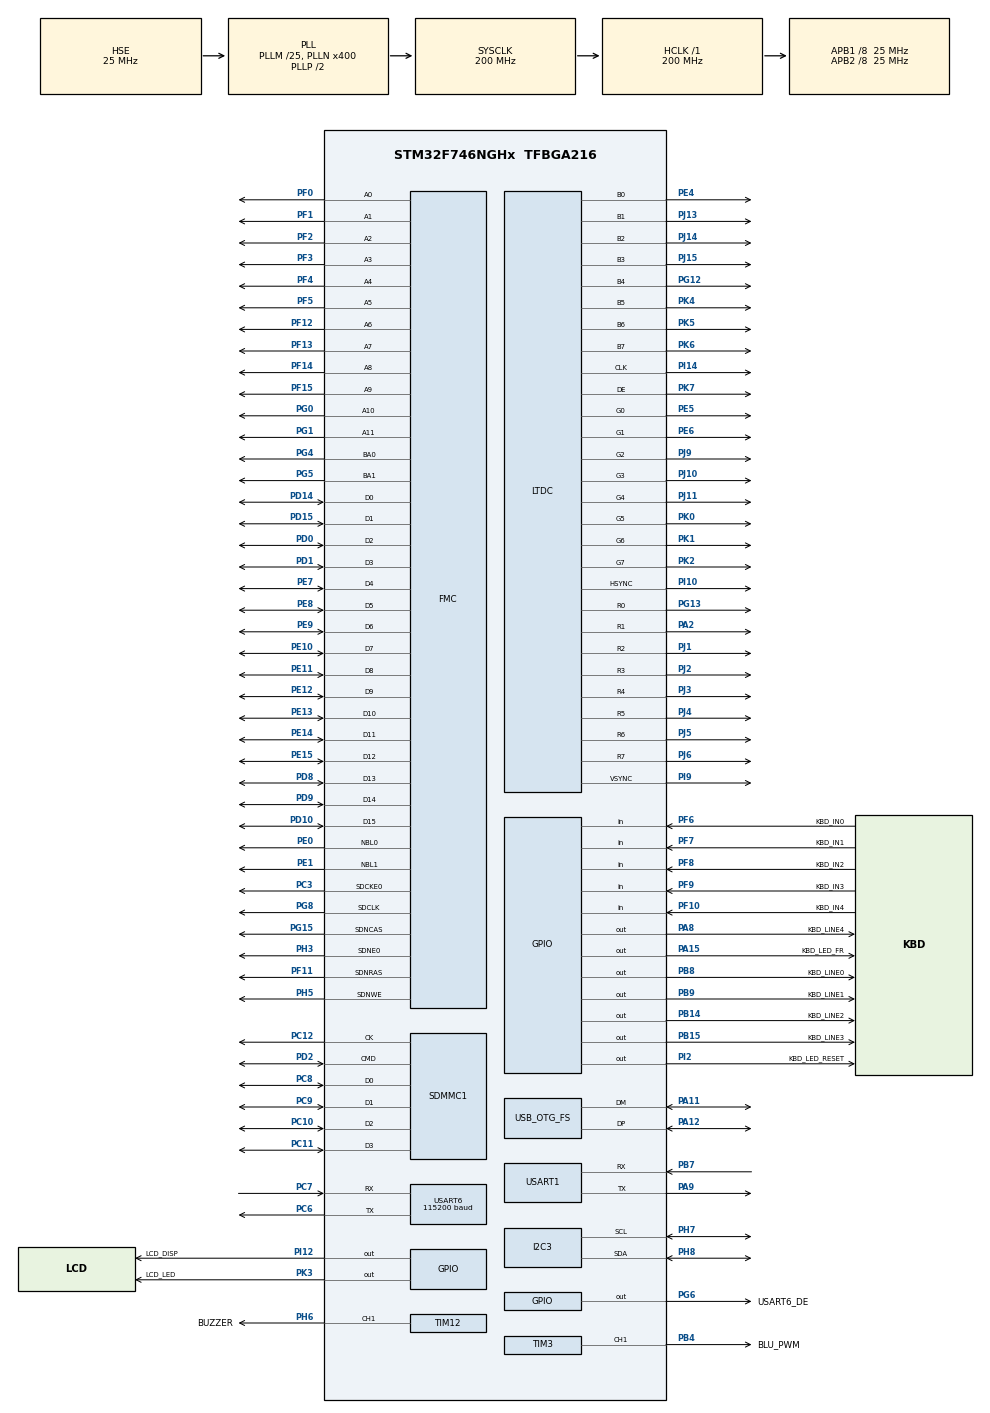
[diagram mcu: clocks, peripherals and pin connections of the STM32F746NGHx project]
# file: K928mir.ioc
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CORTEX_M7.AccessPermission-Cortex_Memory_Protection_Unit_Region0_Settings=MPU_REGION_FULL_ACCESS
CORTEX_M7.BaseAddress-Cortex_Memory_Protection_Unit_Region0_Settings=0xC0000000
CORTEX_M7.CPU_DCache=Enabled
CORTEX_M7.CPU_ICache=Enabled
CORTEX_M7.Enable-Cortex_Memory_Protection_Unit_Region0_Settings=MPU_REGION_ENABLE
CORTEX_M7.IsCacheable-Cortex_Memory_Protection_Unit_Region0_Settings=MPU_ACCESS_CACHEABLE
CORTEX_M7.MPU_Control=MPU_PRIVILEGED_DEFAULT
CORTEX_M7.Size-Cortex_Memory_Protection_Unit_Region0_Settings=MPU_REGION_SIZE_4MB
DMA2D.ColorMode=DMA2D_OUTPUT_RGB565
FATFS.USE_DMA_CODE_SD=0
FATFS._MAX_SS=4096
FMC.CASLatency1=FMC_SDRAM_CAS_LATENCY_2
FMC.ExitSelfRefreshDelay1=6
FMC.LoadToActiveDelay1=2
FMC.RCDDelay1=2
FMC.RPDelay1=2
FMC.ReadBurst1=FMC_SDRAM_RBURST_ENABLE
FMC.ReadPipeDelay1=FMC_SDRAM_RPIPE_DELAY_0
FMC.RowCycleDelay1=6
FMC.RowCycleDelay2=6
FMC.SDClockPeriod1=FMC_SDRAM_CLOCK_PERIOD_2
FMC.SDClockPeriod2=FMC_SDRAM_CLOCK_PERIOD_2
FMC.SelfRefreshTime1=4
FMC.WriteRecoveryTime1=2
I2C3.OwnAddress=112
I2C3.Timing=0x00606092
LTDC.ActiveH=272
LTDC.ActiveW=480
LTDC.Alpha_L0=0
LTDC.FBStartAdress_L1=0
LTDC.HBP=13
LTDC.HFP=32
LTDC.HSync=30
LTDC.ImageHeight_L0=272
LTDC.ImageHeight_L1=272
LTDC.ImageWidth_L0=480
LTDC.ImageWidth_L1=480
LTDC.Layers=1
LTDC.PixelFormat_L0=LTDC_PIXEL_FORMAT_RGB565
LTDC.PixelFormat_L1=LTDC_PIXEL_FORMAT_RGB565
LTDC.VBP=2
LTDC.VFP=2
LTDC.VSync=10
LTDC.WindowX1_L0=480
LTDC.WindowX1_L1=480
LTDC.WindowY1_L0=272
LTDC.WindowY1_L1=272
Mcu.Family=STM32F7
Mcu.Name=STM32F746NGHx
Mcu.Package=TFBGA216
Mcu.UserConstants=UC_LEDLIGHT_PERIOD,50000;UC_MAINTIC_PERIOD,50000
NVIC.LTDC_IRQn=true\:0\:0\:false\:false\:true\:true
NVIC.OTG_FS_IRQn=true\:0\:0\:false\:false\:true\:false
NVIC.PriorityGroup=NVIC_PRIORITYGROUP_4
NVIC.USART1_IRQn=true\:0\:0\:false\:false\:true\:true
NVIC.USART6_IRQn=true\:0\:0\:false\:false\:true\:true
PA11.Mode=Device_Only
PA11.Signal=USB_OTG_FS_DM
PA12.Mode=Device_Only
PA12.Signal=USB_OTG_FS_DP
PA13.Mode=Serial_Wire
PA13.Signal=SYS_JTMS-SWDIO
PA14.Mode=Serial_Wire
PA14.Signal=SYS_JTCK-SWCLK
PA15.GPIO_Label=KBD_LED_FR
PA15.PinState=GPIO_PIN_RESET
PA15.Signal=GPIO_Output
PA2.Mode=RGB888
PA2.Signal=LTDC_R1
PA8.GPIO_Label=KBD_LINE4
PA8.GPIO_ModeDefaultOutputPP=GPIO_MODE_OUTPUT_OD
PA8.PinState=GPIO_PIN_SET
PA8.Signal=GPIO_Output
PA9.Mode=Asynchronous
PA9.Signal=USART1_TX
PB14.GPIO_Label=KBD_LINE2
PB14.GPIO_ModeDefaultOutputPP=GPIO_MODE_OUTPUT_OD
PB14.GPIO_Speed=GPIO_SPEED_FREQ_LOW
PB14.PinState=GPIO_PIN_SET
PB14.Signal=GPIO_Output
PB15.GPIO_Label=KBD_LINE3
PB15.GPIO_ModeDefaultOutputPP=GPIO_MODE_OUTPUT_OD
PB15.PinState=GPIO_PIN_SET
PB15.Signal=GPIO_Output
PB4.GPIO_Label=BLU_PWM
PB4.Signal=S_TIM3_CH1
PB7.Mode=Asynchronous
PB7.Signal=USART1_RX
PB8.GPIO_Label=KBD_LINE0
PB8.GPIO_ModeDefaultOutputPP=GPIO_MODE_OUTPUT_OD
PB8.GPIO_Speed=GPIO_SPEED_FREQ_LOW
PB8.PinState=GPIO_PIN_SET
PB8.Signal=GPIO_Output
PB9.GPIO_Label=KBD_LINE1
PB9.GPIO_ModeDefaultOutputPP=GPIO_MODE_OUTPUT_OD
PB9.GPIO_Speed=GPIO_SPEED_FREQ_LOW
PB9.PinState=GPIO_PIN_SET
PB9.Signal=GPIO_Output
PC10.GPIO_PuPd=GPIO_PULLUP
PC10.Mode=SD_4_bits_Wide_bus
PC10.Signal=SDMMC1_D2
PC11.GPIO_PuPd=GPIO_PULLUP
PC11.Mode=SD_4_bits_Wide_bus
PC11.Signal=SDMMC1_D3
PC12.Mode=SD_4_bits_Wide_bus
PC12.Signal=SDMMC1_CK
PC3.Mode=SdramChipSelect1_1
PC3.Signal=FMC_SDCKE0
PC6.Mode=Asynchronous
PC6.Signal=USART6_TX
PC7.Mode=Asynchronous
PC7.Signal=USART6_RX
PC8.GPIO_PuPd=GPIO_PULLUP
PC8.Mode=SD_4_bits_Wide_bus
PC8.Signal=SDMMC1_D0
PC9.GPIO_PuPd=GPIO_PULLUP
PC9.Mode=SD_4_bits_Wide_bus
PC9.Signal=SDMMC1_D1
PD0.Signal=FMC_D2_DA2
PD1.Signal=FMC_D3_DA3
PD10.Signal=FMC_D15_DA15
PD14.Signal=FMC_D0_DA0
PD15.Signal=FMC_D1_DA1
PD2.GPIO_PuPd=GPIO_PULLUP
PD2.Mode=SD_4_bits_Wide_bus
PD2.Signal=SDMMC1_CMD
PD8.Signal=FMC_D13_DA13
PD9.Signal=FMC_D14_DA14
PE0.Signal=FMC_NBL0
PE1.Signal=FMC_NBL1
PE10.Signal=FMC_D7_DA7
PE11.Signal=FMC_D8_DA8
PE12.Signal=FMC_D9_DA9
PE13.Signal=FMC_D10_DA10
PE14.Signal=FMC_D11_DA11
PE15.Signal=FMC_D12_DA12
PE4.Mode=RGB888
PE4.Signal=LTDC_B0
PE5.Mode=RGB888
PE5.Signal=LTDC_G0
PE6.Mode=RGB888
PE6.Signal=LTDC_G1
PE7.Signal=FMC_D4_DA4
PE8.Signal=FMC_D5_DA5
PE9.Signal=FMC_D6_DA6
PF0.Signal=FMC_A0
PF1.Signal=FMC_A1
PF10.GPIO_Label=KBD_IN4
PF10.Signal=GPIO_Input
PF11.Signal=FMC_SDNRAS
PF12.Signal=FMC_A6
PF13.Signal=FMC_A7
PF14.Signal=FMC_A8
PF15.Signal=FMC_A9
PF2.Signal=FMC_A2
PF3.Signal=FMC_A3
PF4.Signal=FMC_A4
PF5.Signal=FMC_A5
PF6.GPIO_Label=KBD_IN0
PF6.Signal=GPIO_Input
PF7.GPIO_Label=KBD_IN1
PF7.Signal=GPIO_Input
PF8.GPIO_Label=KBD_IN2
PF8.Signal=GPIO_Input
PF9.GPIO_Label=KBD_IN3
PF9.Signal=GPIO_Input
PG0.Signal=FMC_A10
PG1.Signal=FMC_A11
PG12.GPIO_Speed=GPIO_SPEED_FREQ_HIGH
PG12.Mode=RGB888
PG12.Signal=LTDC_B4
PG13.Mode=RGB888
PG13.Signal=LTDC_R0
PG15.Signal=FMC_SDNCAS
PG4.Signal=FMC_A14_BA0
PG5.Signal=FMC_A15_BA1
PG6.GPIO_Label=USART6_DE
PG6.PinState=GPIO_PIN_SET
PG6.Signal=GPIO_Output
PG8.Signal=FMC_SDCLK
PH0/OSC_IN.Mode=HSE-External-Oscillator
PH0/OSC_IN.Signal=RCC_OSC_IN
PH1/OSC_OUT.Mode=HSE-External-Oscillator
PH1/OSC_OUT.Signal=RCC_OSC_OUT
PH3.Mode=SdramChipSelect1_1
PH3.Signal=FMC_SDNE0
PH5.Signal=FMC_SDNWE
PH6.GPIO_Label=BUZZER
PH6.GPIO_PuPd=GPIO_PULLUP
PH6.Signal=S_TIM12_CH1
PH7.Mode=I2C
PH7.Signal=I2C3_SCL
PH8.Mode=I2C
PH8.Signal=I2C3_SDA
PI10.GPIO_Speed=GPIO_SPEED_FREQ_HIGH
PI10.Mode=RGB888
PI10.Signal=LTDC_HSYNC
PI12.GPIO_Label=LCD_DISP
PI12.PinState=GPIO_PIN_RESET
PI12.Signal=GPIO_Output
PI14.GPIO_Speed=GPIO_SPEED_FREQ_HIGH
PI14.Mode=RGB888
PI14.Signal=LTDC_CLK
PI2.GPIO_Label=KBD_LED_RESET
PI2.PinState=GPIO_PIN_RESET
PI2.Signal=GPIO_Output
PI9.GPIO_Speed=GPIO_SPEED_FREQ_HIGH
PI9.Mode=RGB888
PI9.Signal=LTDC_VSYNC
PJ1.GPIO_Speed=GPIO_SPEED_FREQ_HIGH
PJ1.Mode=RGB888
PJ1.Signal=LTDC_R2
PJ10.GPIO_Speed=GPIO_SPEED_FREQ_HIGH
PJ10.Mode=RGB888
PJ10.Signal=LTDC_G3
PJ11.GPIO_Speed=GPIO_SPEED_FREQ_HIGH
PJ11.Mode=RGB888
PJ11.Signal=LTDC_G4
PJ13.Mode=RGB888
PJ13.Signal=LTDC_B1
PJ14.GPIO_Speed=GPIO_SPEED_FREQ_HIGH
PJ14.Mode=RGB888
PJ14.Signal=LTDC_B2
PJ15.GPIO_Speed=GPIO_SPEED_FREQ_HIGH
PJ15.Mode=RGB888
PJ15.Signal=LTDC_B3
PJ2.GPIO_Speed=GPIO_SPEED_FREQ_HIGH
PJ2.Mode=RGB888
PJ2.Signal=LTDC_R3
PJ3.GPIO_Speed=GPIO_SPEED_FREQ_HIGH
PJ3.Mode=RGB888
PJ3.Signal=LTDC_R4
PJ4.GPIO_Speed=GPIO_SPEED_FREQ_HIGH
PJ4.Mode=RGB888
PJ4.Signal=LTDC_R5
PJ5.GPIO_Speed=GPIO_SPEED_FREQ_HIGH
PJ5.Mode=RGB888
PJ5.Signal=LTDC_R6
PJ6.GPIO_Speed=GPIO_SPEED_FREQ_HIGH
PJ6.Mode=RGB888
PJ6.Signal=LTDC_R7
PJ9.GPIO_Speed=GPIO_SPEED_FREQ_HIGH
PJ9.Mode=RGB888
PJ9.Signal=LTDC_G2
PK0.GPIO_Speed=GPIO_SPEED_FREQ_HIGH
PK0.Mode=RGB888
PK0.Signal=LTDC_G5
PK1.GPIO_Speed=GPIO_SPEED_FREQ_HIGH
PK1.Mode=RGB888
PK1.Signal=LTDC_G6
PK2.GPIO_Speed=GPIO_SPEED_FREQ_HIGH
PK2.Mode=RGB888
PK2.Signal=LTDC_G7
PK3.GPIO_Label=LCD_LED
PK3.PinState=GPIO_PIN_RESET
PK3.Signal=GPIO_Output
PK4.GPIO_Speed=GPIO_SPEED_FREQ_HIGH
PK4.Mode=RGB888
PK4.Signal=LTDC_B5
PK5.GPIO_Speed=GPIO_SPEED_FREQ_HIGH
PK5.Mode=RGB888
PK5.Signal=LTDC_B6
PK6.GPIO_Speed=GPIO_SPEED_FREQ_HIGH
PK6.Mode=RGB888
PK6.Signal=LTDC_B7
PK7.GPIO_Speed=GPIO_SPEED_FREQ_HIGH
PK7.Mode=RGB888
PK7.Signal=LTDC_DE
ProjectManager.HeapSize=0x4000
ProjectManager.StackSize=0x8000
ProjectManager.TargetToolchain=EWARM
RCC.AHBFreq_Value=200000000
RCC.APB1CLKDivider=RCC_HCLK_DIV8
RCC.APB1Freq_Value=25000000
RCC.APB1TimFreq_Value=50000000
RCC.APB2CLKDivider=RCC_HCLK_DIV8
RCC.APB2Freq_Value=25000000
RCC.APB2TimFreq_Value=50000000
RCC.CortexFreq_Value=200000000
RCC.HCLKFreq_Value=200000000
RCC.HSE_VALUE=25000000
RCC.HSI_VALUE=16000000
RCC.LSE_VALUE=32768
RCC.PLL48CLockSelection=RCC_CLK48SOURCE_PLLSAIP
RCC.PLLM=25
RCC.PLLN=400
RCC.PLLQ=8
RCC.PLLSAIP=RCC_PLLSAIP_DIV4
RCC.PLLSAIR=5
RCC.PLLSAIRDiv=RCC_PLLSAIDIVR_4
RCC.SDMMCClockSelection=RCC_SDMMC1CLKSOURCE_CLK48
RCC.SYSCLKFreq_VALUE=200000000
RCC.SYSCLKSource=RCC_SYSCLKSOURCE_PLLCLK
RCC.USBFreq_Value=48000000
RCC.VCOOutputFreq_Value=400000000
SH.FMC_A0.0=FMC_A0,12b-sda1
SH.FMC_A1.0=FMC_A1,12b-sda1
SH.FMC_A10.0=FMC_A10,12b-sda1
SH.FMC_A11.0=FMC_A11,12b-sda1
SH.FMC_A14_BA0.0=FMC_BA0,FourSdramBanks1
SH.FMC_A15_BA1.0=FMC_BA1,FourSdramBanks1
SH.FMC_A2.0=FMC_A2,12b-sda1
SH.FMC_A3.0=FMC_A3,12b-sda1
SH.FMC_A4.0=FMC_A4,12b-sda1
SH.FMC_A5.0=FMC_A5,12b-sda1
SH.FMC_A6.0=FMC_A6,12b-sda1
SH.FMC_A7.0=FMC_A7,12b-sda1
SH.FMC_A8.0=FMC_A8,12b-sda1
SH.FMC_A9.0=FMC_A9,12b-sda1
SH.FMC_D0_DA0.0=FMC_D0,sd-16b-d1
SH.FMC_D10_DA10.0=FMC_D10,sd-16b-d1
SH.FMC_D11_DA11.0=FMC_D11,sd-16b-d1
SH.FMC_D12_DA12.0=FMC_D12,sd-16b-d1
SH.FMC_D13_DA13.0=FMC_D13,sd-16b-d1
SH.FMC_D14_DA14.0=FMC_D14,sd-16b-d1
SH.FMC_D15_DA15.0=FMC_D15,sd-16b-d1
SH.FMC_D1_DA1.0=FMC_D1,sd-16b-d1
SH.FMC_D2_DA2.0=FMC_D2,sd-16b-d1
SH.FMC_D3_DA3.0=FMC_D3,sd-16b-d1
SH.FMC_D4_DA4.0=FMC_D4,sd-16b-d1
SH.FMC_D5_DA5.0=FMC_D5,sd-16b-d1
SH.FMC_D6_DA6.0=FMC_D6,sd-16b-d1
SH.FMC_D7_DA7.0=FMC_D7,sd-16b-d1
SH.FMC_D8_DA8.0=FMC_D8,sd-16b-d1
SH.FMC_D9_DA9.0=FMC_D9,sd-16b-d1
SH.FMC_NBL0.0=FMC_NBL0,Sd2ByteEnable1
SH.FMC_NBL1.0=FMC_NBL1,Sd2ByteEnable1
SH.FMC_SDCLK.0=FMC_SDCLK,12b-sda1
SH.FMC_SDNCAS.0=FMC_SDNCAS,12b-sda1
SH.FMC_SDNRAS.0=FMC_SDNRAS,12b-sda1
SH.FMC_SDNWE.0=FMC_SDNWE,12b-sda1
SH.S_TIM12_CH1.0=TIM12_CH1,PWM Generation1 CH1
SH.S_TIM3_CH1.0=TIM3_CH1,PWM Generation1 CH1
TIM10.ClockDivision=TIM_CLOCKDIVISION_DIV1
TIM10.Period=UC_MAINTIC_PERIOD
TIM10.Prescaler=1
TIM12.Channel-PWM\ Generation1\ CH1=TIM_CHANNEL_1
TIM12.OCFastMode_PWM-PWM\ Generation1\ CH1=TIM_OCFAST_DISABLE
TIM12.OCPolarity_1=TIM_OCPOLARITY_HIGH
TIM12.Period=4999
TIM12.Prescaler=4
TIM12.Pulse-PWM\ Generation1\ CH1=2500
TIM3.AutoReloadPreload=TIM_AUTORELOAD_PRELOAD_ENABLE
TIM3.Channel-PWM\ Generation1\ CH1=TIM_CHANNEL_1
TIM3.ClockDivision=TIM_CLOCKDIVISION_DIV1
TIM3.OCFastMode_PWM-PWM\ Generation1\ CH1=TIM_OCFAST_ENABLE
TIM3.OCMode_PWM-PWM\ Generation1\ CH1=TIM_OCMODE_PWM2
TIM3.Period=UC_LEDLIGHT_PERIOD
TIM3.Prescaler=6
TIM3.Pulse-PWM\ Generation1\ CH1=(UC_LEDLIGHT_PERIOD / 10)*9
USART1.Parity=PARITY_EVEN
USART1.VirtualMode-Asynchronous=VM_ASYNC
USART1.WordLength=WORDLENGTH_9B
USART6.BaudRate=115200
USART6.Parity=PARITY_EVEN
USART6.VirtualMode-Asynchronous=VM_ASYNC
USART6.WordLength=WORDLENGTH_9B
USB_DEVICE.CLASS_NAME_FS=CDC
USB_DEVICE.VirtualMode-CDC_FS=Cdc
USB_DEVICE.VirtualModeFS=Cdc_FS
USB_OTG_FS.VirtualMode=Device_Only
VP_DMA2D_VS_DMA2D.Mode=DMA2D_Activate
VP_FATFS_VS_SDIO.Mode=SDIO
VP_RNG_VS_RNG.Mode=RNG_Activate
VP_TIM10_VS_ClockSourceINT.Mode=Enable_Timer
VP_TIM3_VS_ClockSourceINT.Mode=Internal
VP_USB_DEVICE_VS_USB_DEVICE_CDC_FS.Mode=CDC_FS
board=K928mir

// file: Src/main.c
/**
  ******************************************************************************
  * @file           : main.c
  * @brief          : Main program body
  ******************************************************************************
  * This notice applies to any and all portions of this file
  * that are not between comment pairs USER CODE BEGIN and
  * USER CODE END. Other portions of this file, whether
  * inserted by the user or by software development tools
  * are owned by their respective copyright owners.
  *
  * Copyright (c) 2019 STMicroelectronics International N.V.
  * All rights reserved.
  *
  * Redistribution and use in source and binary forms, with or without
  * modification, are permitted, provided that the following conditions are met:
  *
  * 1. Redistribution of source code must retain the above copyright notice,
  *    this list of conditions and the following disclaimer.
  * 2. Redistributions in binary form must reproduce the above copyright notice,
  *    this list of conditions and the following disclaimer in the documentation
  *    and/or other materials provided with the distribution.
  * 3. Neither the name of STMicroelectronics nor the names of other
  *    contributors to this software may be used to endorse or promote products
  *    derived from this software without specific written permission.
  * 4. This software, including modifications and/or derivative works of this
  *    software, must execute solely and exclusively on microcontroller or
  *    microprocessor devices manufactured by or for STMicroelectronics.
  * 5. Redistribution and use of this software other than as permitted under
  *    this license is void and will automatically terminate your rights under
  *    this license.
  *
  * THIS SOFTWARE IS PROVIDED BY STMICROELECTRONICS AND CONTRIBUTORS "AS IS"
  * AND ANY EXPRESS, IMPLIED OR STATUTORY WARRANTIES, INCLUDING, BUT NOT
  * LIMITED TO, THE IMPLIED WARRANTIES OF MERCHANTABILITY, FITNESS FOR A
  * PARTICULAR PURPOSE AND NON-INFRINGEMENT OF THIRD PARTY INTELLECTUAL PROPERTY
  * RIGHTS ARE DISCLAIMED TO THE FULLEST EXTENT PERMITTED BY LAW. IN NO EVENT
  * SHALL STMICROELECTRONICS OR CONTRIBUTORS BE LIABLE FOR ANY DIRECT, INDIRECT,
  * INCIDENTAL, SPECIAL, EXEMPLARY, OR CONSEQUENTIAL DAMAGES (INCLUDING, BUT NOT
  * LIMITED TO, PROCUREMENT OF SUBSTITUTE GOODS OR SERVICES; LOSS OF USE, DATA,
  * OR PROFITS; OR BUSINESS INTERRUPTION) HOWEVER CAUSED AND ON ANY THEORY OF
  * LIABILITY, WHETHER IN CONTRACT, STRICT LIABILITY, OR TORT (INCLUDING
  * NEGLIGENCE OR OTHERWISE) ARISING IN ANY WAY OUT OF THE USE OF THIS SOFTWARE,
  * EVEN IF ADVISED OF THE POSSIBILITY OF SUCH DAMAGE.
  *
  ******************************************************************************
  */
#include "main.h"
#include "stm32f7xx_hal.h"
#include "fatfs.h"
#include "usb_device.h"

/* USER CODE BEGIN Includes */
#include "laa_user_code.h"
/* USER CODE END Includes */

DMA2D_HandleTypeDef hdma2d;

I2C_HandleTypeDef hi2c3;

LTDC_HandleTypeDef hltdc;

RNG_HandleTypeDef hrng;

SD_HandleTypeDef hsd1;

TIM_HandleTypeDef htim3;
TIM_HandleTypeDef htim10;
TIM_HandleTypeDef htim12;

UART_HandleTypeDef huart1;
UART_HandleTypeDef huart6;

SDRAM_HandleTypeDef hsdram1;

/* USER CODE BEGIN PV */
/* Private variables ---------------------------------------------------------*/

/* USER CODE END PV */

void SystemClock_Config(void);
static void MPU_Config(void);
static void MX_GPIO_Init(void);
static void MX_TIM3_Init(void);
static void MX_FMC_Init(void);
static void MX_TIM10_Init(void);
static void MX_USART6_UART_Init(void);
static void MX_LTDC_Init(void);
static void MX_USART1_UART_Init(void);
static void MX_DMA2D_Init(void);
static void MX_RNG_Init(void);
static void MX_SDMMC1_SD_Init(void);
static void MX_TIM12_Init(void);
static void MX_I2C3_Init(void);

void HAL_TIM_MspPostInit(TIM_HandleTypeDef *htim);

/* USER CODE BEGIN PFP */
/* Private function prototypes -----------------------------------------------*/

/* USER CODE END PFP */

int main(void)
{

  /* MPU Configuration----------------------------------------------------------*/
  MPU_Config();

  /* Enable I-Cache-------------------------------------------------------------*/
  SCB_EnableICache();

  /* Enable D-Cache-------------------------------------------------------------*/
  SCB_EnableDCache();

  /* MCU Configuration----------------------------------------------------------*/

  /* Reset of all peripherals, Initializes the Flash interface and the Systick. */
  HAL_Init();

  /* Configure the system clock */
  SystemClock_Config();

  /* Initialize all configured peripherals */
  MX_GPIO_Init();
  MX_TIM3_Init();
  MX_FMC_Init();
  MX_TIM10_Init();
  MX_USART6_UART_Init();
  MX_LTDC_Init();
  MX_USART1_UART_Init();
  MX_DMA2D_Init();
  MX_RNG_Init();
  MX_SDMMC1_SD_Init();
  MX_FATFS_Init();
  MX_TIM12_Init();
  MX_I2C3_Init();
  MX_USB_DEVICE_Init();
  /* USER CODE BEGIN 2 */
  userMain();
  /* USER CODE END 2 */

  /* Infinite loop */
  while (1)
  {

  }

}

void SystemClock_Config(void)
{

  RCC_OscInitTypeDef RCC_OscInitStruct;
  RCC_ClkInitTypeDef RCC_ClkInitStruct;
  RCC_PeriphCLKInitTypeDef PeriphClkInitStruct;

    /**Configure the main internal regulator output voltage
    */
  __HAL_RCC_PWR_CLK_ENABLE();

  __HAL_PWR_VOLTAGESCALING_CONFIG(PWR_REGULATOR_VOLTAGE_SCALE1);

    /**Initializes the CPU, AHB and APB busses clocks
    */
  RCC_OscInitStruct.OscillatorType = RCC_OSCILLATORTYPE_HSE;
  RCC_OscInitStruct.HSEState = RCC_HSE_ON;
  RCC_OscInitStruct.PLL.PLLState = RCC_PLL_ON;
  RCC_OscInitStruct.PLL.PLLSource = RCC_PLLSOURCE_HSE;
  RCC_OscInitStruct.PLL.PLLM = 25;
  RCC_OscInitStruct.PLL.PLLN = 400;
  RCC_OscInitStruct.PLL.PLLP = RCC_PLLP_DIV2;
  RCC_OscInitStruct.PLL.PLLQ = 8;
  if (HAL_RCC_OscConfig(&RCC_OscInitStruct) != HAL_OK)
  {
    _Error_Handler(__FILE__, __LINE__);
  }

    /**Activate the Over-Drive mode
    */
  if (HAL_PWREx_EnableOverDrive() != HAL_OK)
  {
    _Error_Handler(__FILE__, __LINE__);
  }

    /**Initializes the CPU, AHB and APB busses clocks
    */
  RCC_ClkInitStruct.ClockType = RCC_CLOCKTYPE_HCLK|RCC_CLOCKTYPE_SYSCLK
                              |RCC_CLOCKTYPE_PCLK1|RCC_CLOCKTYPE_PCLK2;
  RCC_ClkInitStruct.SYSCLKSource = RCC_SYSCLKSOURCE_PLLCLK;
  RCC_ClkInitStruct.AHBCLKDivider = RCC_SYSCLK_DIV1;
  RCC_ClkInitStruct.APB1CLKDivider = RCC_HCLK_DIV8;
  RCC_ClkInitStruct.APB2CLKDivider = RCC_HCLK_DIV8;

  if (HAL_RCC_ClockConfig(&RCC_ClkInitStruct, FLASH_LATENCY_6) != HAL_OK)
  {
    _Error_Handler(__FILE__, __LINE__);
  }

  PeriphClkInitStruct.PeriphClockSelection = RCC_PERIPHCLK_LTDC|RCC_PERIPHCLK_USART1
                              |RCC_PERIPHCLK_USART6|RCC_PERIPHCLK_I2C3
                              |RCC_PERIPHCLK_SDMMC1|RCC_PERIPHCLK_CLK48;
  PeriphClkInitStruct.PLLSAI.PLLSAIN = 192;
  PeriphClkInitStruct.PLLSAI.PLLSAIR = 5;
  PeriphClkInitStruct.PLLSAI.PLLSAIQ = 2;
  PeriphClkInitStruct.PLLSAI.PLLSAIP = RCC_PLLSAIP_DIV4;
  PeriphClkInitStruct.PLLSAIDivQ = 1;
  PeriphClkInitStruct.PLLSAIDivR = RCC_PLLSAIDIVR_4;
  PeriphClkInitStruct.Usart1ClockSelection = RCC_USART1CLKSOURCE_PCLK2;
  PeriphClkInitStruct.Usart6ClockSelection = RCC_USART6CLKSOURCE_PCLK2;
  PeriphClkInitStruct.I2c3ClockSelection = RCC_I2C3CLKSOURCE_PCLK1;
  PeriphClkInitStruct.Clk48ClockSelection = RCC_CLK48SOURCE_PLLSAIP;
  PeriphClkInitStruct.Sdmmc1ClockSelection = RCC_SDMMC1CLKSOURCE_CLK48;
  if (HAL_RCCEx_PeriphCLKConfig(&PeriphClkInitStruct) != HAL_OK)
  {
    _Error_Handler(__FILE__, __LINE__);
  }

    /**Configure the Systick interrupt time
    */
  HAL_SYSTICK_Config(HAL_RCC_GetHCLKFreq()/1000);

    /**Configure the Systick
    */
  HAL_SYSTICK_CLKSourceConfig(SYSTICK_CLKSOURCE_HCLK);

  /* SysTick_IRQn interrupt configuration */
  HAL_NVIC_SetPriority(SysTick_IRQn, 0, 0);
}

/* DMA2D init function */
static void MX_DMA2D_Init(void)
{

  hdma2d.Instance = DMA2D;
  hdma2d.Init.Mode = DMA2D_M2M;
  hdma2d.Init.ColorMode = DMA2D_OUTPUT_RGB565;
  hdma2d.Init.OutputOffset = 0;
  hdma2d.LayerCfg[1].InputOffset = 0;
  hdma2d.LayerCfg[1].InputColorMode = DMA2D_INPUT_RGB565;
  hdma2d.LayerCfg[1].AlphaMode = DMA2D_NO_MODIF_ALPHA;
  hdma2d.LayerCfg[1].InputAlpha = 0;
  if (HAL_DMA2D_Init(&hdma2d) != HAL_OK)
  {
    _Error_Handler(__FILE__, __LINE__);
  }

  if (HAL_DMA2D_ConfigLayer(&hdma2d, 1) != HAL_OK)
  {
    _Error_Handler(__FILE__, __LINE__);
  }

}

/* I2C3 init function */
static void MX_I2C3_Init(void)
{

  hi2c3.Instance = I2C3;
  hi2c3.Init.Timing = 0x00606092;
  hi2c3.Init.OwnAddress1 = 224;
  hi2c3.Init.AddressingMode = I2C_ADDRESSINGMODE_7BIT;
  hi2c3.Init.DualAddressMode = I2C_DUALADDRESS_DISABLE;
  hi2c3.Init.OwnAddress2 = 0;
  hi2c3.Init.OwnAddress2Masks = I2C_OA2_NOMASK;
  hi2c3.Init.GeneralCallMode = I2C_GENERALCALL_DISABLE;
  hi2c3.Init.NoStretchMode = I2C_NOSTRETCH_DISABLE;
  if (HAL_I2C_Init(&hi2c3) != HAL_OK)
  {
    _Error_Handler(__FILE__, __LINE__);
  }

    /**Configure Analogue filter
    */
  if (HAL_I2CEx_ConfigAnalogFilter(&hi2c3, I2C_ANALOGFILTER_ENABLE) != HAL_OK)
  {
    _Error_Handler(__FILE__, __LINE__);
  }

    /**Configure Digital filter
    */
  if (HAL_I2CEx_ConfigDigitalFilter(&hi2c3, 0) != HAL_OK)
  {
    _Error_Handler(__FILE__, __LINE__);
  }

}

/* LTDC init function */
static void MX_LTDC_Init(void)
{

  LTDC_LayerCfgTypeDef pLayerCfg;
  LTDC_LayerCfgTypeDef pLayerCfg1;

  hltdc.Instance = LTDC;
  hltdc.Init.HSPolarity = LTDC_HSPOLARITY_AL;
  hltdc.Init.VSPolarity = LTDC_VSPOLARITY_AL;
  hltdc.Init.DEPolarity = LTDC_DEPOLARITY_AL;
  hltdc.Init.PCPolarity = LTDC_PCPOLARITY_IPC;
  hltdc.Init.HorizontalSync = 29;
  hltdc.Init.VerticalSync = 9;
  hltdc.Init.AccumulatedHBP = 42;
  hltdc.Init.AccumulatedVBP = 11;
  hltdc.Init.AccumulatedActiveW = 522;
  hltdc.Init.AccumulatedActiveH = 283;
  hltdc.Init.TotalWidth = 554;
  hltdc.Init.TotalHeigh = 285;
  hltdc.Init.Backcolor.Blue = 0;
  hltdc.Init.Backcolor.Green = 0;
  hltdc.Init.Backcolor.Red = 0;
  if (HAL_LTDC_Init(&hltdc) != HAL_OK)
  {
    _Error_Handler(__FILE__, __LINE__);
  }

  pLayerCfg.WindowX0 = 0;
  pLayerCfg.WindowX1 = 480;
  pLayerCfg.WindowY0 = 0;
  pLayerCfg.WindowY1 = 272;
  pLayerCfg.PixelFormat = LTDC_PIXEL_FORMAT_RGB565;
  pLayerCfg.Alpha = 0;
  pLayerCfg.Alpha0 = 0;
  pLayerCfg.BlendingFactor1 = LTDC_BLENDING_FACTOR1_CA;
  pLayerCfg.BlendingFactor2 = LTDC_BLENDING_FACTOR2_CA;
  pLayerCfg.FBStartAdress = 0;
  pLayerCfg.ImageWidth = 480;
  pLayerCfg.ImageHeight = 272;
  pLayerCfg.Backcolor.Blue = 0;
  pLayerCfg.Backcolor.Green = 0;
  pLayerCfg.Backcolor.Red = 0;
  if (HAL_LTDC_ConfigLayer(&hltdc, &pLayerCfg, 0) != HAL_OK)
  {
    _Error_Handler(__FILE__, __LINE__);
  }

  pLayerCfg1.WindowX0 = 0;
  pLayerCfg1.WindowX1 = 480;
  pLayerCfg1.WindowY0 = 0;
  pLayerCfg1.WindowY1 = 272;
  pLayerCfg1.PixelFormat = LTDC_PIXEL_FORMAT_RGB565;
  pLayerCfg1.Alpha = 0;
  pLayerCfg1.Alpha0 = 0;
  pLayerCfg1.BlendingFactor1 = LTDC_BLENDING_FACTOR1_CA;
  pLayerCfg1.BlendingFactor2 = LTDC_BLENDING_FACTOR2_CA;
  pLayerCfg1.FBStartAdress = 0;
  pLayerCfg1.ImageWidth = 480;
  pLayerCfg1.ImageHeight = 272;
  pLayerCfg1.Backcolor.Blue = 0;
  pLayerCfg1.Backcolor.Green = 0;
  pLayerCfg1.Backcolor.Red = 0;
  if (HAL_LTDC_ConfigLayer(&hltdc, &pLayerCfg1, 1) != HAL_OK)
  {
    _Error_Handler(__FILE__, __LINE__);
  }

}

/* RNG init function */
static void MX_RNG_Init(void)
{

  hrng.Instance = RNG;
  if (HAL_RNG_Init(&hrng) != HAL_OK)
  {
    _Error_Handler(__FILE__, __LINE__);
  }

}

/* SDMMC1 init function */
static void MX_SDMMC1_SD_Init(void)
{

  hsd1.Instance = SDMMC1;
  hsd1.Init.ClockEdge = SDMMC_CLOCK_EDGE_RISING;
  hsd1.Init.ClockBypass = SDMMC_CLOCK_BYPASS_DISABLE;
  hsd1.Init.ClockPowerSave = SDMMC_CLOCK_POWER_SAVE_DISABLE;
  hsd1.Init.BusWide = SDMMC_BUS_WIDE_1B;
  hsd1.Init.HardwareFlowControl = SDMMC_HARDWARE_FLOW_CONTROL_DISABLE;
  hsd1.Init.ClockDiv = 0;

}

/* TIM3 init function */
static void MX_TIM3_Init(void)
{

  TIM_ClockConfigTypeDef sClockSourceConfig;
  TIM_MasterConfigTypeDef sMasterConfig;
  TIM_OC_InitTypeDef sConfigOC;

  htim3.Instance = TIM3;
  htim3.Init.Prescaler = 6;
  htim3.Init.CounterMode = TIM_COUNTERMODE_UP;
  htim3.Init.Period = UC_LEDLIGHT_PERIOD;
  htim3.Init.ClockDivision = TIM_CLOCKDIVISION_DIV1;
  htim3.Init.AutoReloadPreload = TIM_AUTORELOAD_PRELOAD_ENABLE;
  if (HAL_TIM_Base_Init(&htim3) != HAL_OK)
  {
    _Error_Handler(__FILE__, __LINE__);
  }

  sClockSourceConfig.ClockSource = TIM_CLOCKSOURCE_INTERNAL;
  if (HAL_TIM_ConfigClockSource(&htim3, &sClockSourceConfig) != HAL_OK)
  {
    _Error_Handler(__FILE__, __LINE__);
  }

  if (HAL_TIM_PWM_Init(&htim3) != HAL_OK)
  {
    _Error_Handler(__FILE__, __LINE__);
  }

  sMasterConfig.MasterOutputTrigger = TIM_TRGO_RESET;
  sMasterConfig.MasterSlaveMode = TIM_MASTERSLAVEMODE_DISABLE;
  if (HAL_TIMEx_MasterConfigSynchronization(&htim3, &sMasterConfig) != HAL_OK)
  {
    _Error_Handler(__FILE__, __LINE__);
  }

  sConfigOC.OCMode = TIM_OCMODE_PWM2;
  sConfigOC.Pulse = (UC_LEDLIGHT_PERIOD / 10)*9;
  sConfigOC.OCPolarity = TIM_OCPOLARITY_HIGH;
  sConfigOC.OCFastMode = TIM_OCFAST_ENABLE;
  if (HAL_TIM_PWM_ConfigChannel(&htim3, &sConfigOC, TIM_CHANNEL_1) != HAL_OK)
  {
    _Error_Handler(__FILE__, __LINE__);
  }

  HAL_TIM_MspPostInit(&htim3);

}

/* TIM10 init function */
static void MX_TIM10_Init(void)
{

  htim10.Instance = TIM10;
  htim10.Init.Prescaler = 1;
  htim10.Init.CounterMode = TIM_COUNTERMODE_UP;
  htim10.Init.Period = UC_MAINTIC_PERIOD;
  htim10.Init.ClockDivision = TIM_CLOCKDIVISION_DIV1;
  htim10.Init.AutoReloadPreload = TIM_AUTORELOAD_PRELOAD_DISABLE;
  if (HAL_TIM_Base_Init(&htim10) != HAL_OK)
  {
    _Error_Handler(__FILE__, __LINE__);
  }

}

/* TIM12 init function */
static void MX_TIM12_Init(void)
{

  TIM_OC_InitTypeDef sConfigOC;

  htim12.Instance = TIM12;
  htim12.Init.Prescaler = 4;
  htim12.Init.CounterMode = TIM_COUNTERMODE_UP;
  htim12.Init.Period = 4999;
  htim12.Init.ClockDivision = TIM_CLOCKDIVISION_DIV1;
  htim12.Init.AutoReloadPreload = TIM_AUTORELOAD_PRELOAD_DISABLE;
  if (HAL_TIM_PWM_Init(&htim12) != HAL_OK)
  {
    _Error_Handler(__FILE__, __LINE__);
  }

  sConfigOC.OCMode = TIM_OCMODE_PWM1;
  sConfigOC.Pulse = 2500;
  sConfigOC.OCPolarity = TIM_OCPOLARITY_HIGH;
  sConfigOC.OCFastMode = TIM_OCFAST_DISABLE;
  if (HAL_TIM_PWM_ConfigChannel(&htim12, &sConfigOC, TIM_CHANNEL_1) != HAL_OK)
  {
    _Error_Handler(__FILE__, __LINE__);
  }

  HAL_TIM_MspPostInit(&htim12);

}

/* USART1 init function */
static void MX_USART1_UART_Init(void)
{

  huart1.Instance = USART1;
  huart1.Init.BaudRate = 115200;
  huart1.Init.WordLength = UART_WORDLENGTH_9B;
  huart1.Init.StopBits = UART_STOPBITS_1;
  huart1.Init.Parity = UART_PARITY_EVEN;
  huart1.Init.Mode = UART_MODE_TX_RX;
  huart1.Init.HwFlowCtl = UART_HWCONTROL_NONE;
  huart1.Init.OverSampling = UART_OVERSAMPLING_16;
  huart1.Init.OneBitSampling = UART_ONE_BIT_SAMPLE_DISABLE;
  huart1.AdvancedInit.AdvFeatureInit = UART_ADVFEATURE_NO_INIT;
  if (HAL_UART_Init(&huart1) != HAL_OK)
  {
    _Error_Handler(__FILE__, __LINE__);
  }

}

/* USART6 init function */
static void MX_USART6_UART_Init(void)
{

  huart6.Instance = USART6;
  huart6.Init.BaudRate = 115200;
  huart6.Init.WordLength = UART_WORDLENGTH_9B;
  huart6.Init.StopBits = UART_STOPBITS_1;
  huart6.Init.Parity = UART_PARITY_EVEN;
  huart6.Init.Mode = UART_MODE_TX_RX;
  huart6.Init.HwFlowCtl = UART_HWCONTROL_NONE;
  huart6.Init.OverSampling = UART_OVERSAMPLING_16;
  huart6.Init.OneBitSampling = UART_ONE_BIT_SAMPLE_DISABLE;
  huart6.AdvancedInit.AdvFeatureInit = UART_ADVFEATURE_NO_INIT;
  if (HAL_UART_Init(&huart6) != HAL_OK)
  {
    _Error_Handler(__FILE__, __LINE__);
  }

}

/* FMC initialization function */
static void MX_FMC_Init(void)
{
  FMC_SDRAM_TimingTypeDef SdramTiming;

  /** Perform the SDRAM1 memory initialization sequence
  */
  hsdram1.Instance = FMC_SDRAM_DEVICE;
  /* hsdram1.Init */
  hsdram1.Init.SDBank = FMC_SDRAM_BANK1;
  hsdram1.Init.ColumnBitsNumber = FMC_SDRAM_COLUMN_BITS_NUM_8;
  hsdram1.Init.RowBitsNumber = FMC_SDRAM_ROW_BITS_NUM_12;
  hsdram1.Init.MemoryDataWidth = FMC_SDRAM_MEM_BUS_WIDTH_16;
  hsdram1.Init.InternalBankNumber = FMC_SDRAM_INTERN_BANKS_NUM_4;
  hsdram1.Init.CASLatency = FMC_SDRAM_CAS_LATENCY_2;
  hsdram1.Init.WriteProtection = FMC_SDRAM_WRITE_PROTECTION_DISABLE;
  hsdram1.Init.SDClockPeriod = FMC_SDRAM_CLOCK_PERIOD_2;
  hsdram1.Init.ReadBurst = FMC_SDRAM_RBURST_ENABLE;
  hsdram1.Init.ReadPipeDelay = FMC_SDRAM_RPIPE_DELAY_0;
  /* SdramTiming */
  SdramTiming.LoadToActiveDelay = 2;
  SdramTiming.ExitSelfRefreshDelay = 6;
  SdramTiming.SelfRefreshTime = 4;
  SdramTiming.RowCycleDelay = 6;
  SdramTiming.WriteRecoveryTime = 2;
  SdramTiming.RPDelay = 2;
  SdramTiming.RCDDelay = 2;

  if (HAL_SDRAM_Init(&hsdram1, &SdramTiming) != HAL_OK)
  {
    _Error_Handler(__FILE__, __LINE__);
  }

}

/** Configure pins as
        * Analog
        * Input
        * Output
        * EVENT_OUT
        * EXTI
*/
static void MX_GPIO_Init(void)
{

  GPIO_InitTypeDef GPIO_InitStruct;

  /* GPIO Ports Clock Enable */
  __HAL_RCC_GPIOE_CLK_ENABLE();
  __HAL_RCC_GPIOB_CLK_ENABLE();
  __HAL_RCC_GPIOC_CLK_ENABLE();
  __HAL_RCC_GPIOA_CLK_ENABLE();
  __HAL_RCC_GPIOG_CLK_ENABLE();
  __HAL_RCC_GPIOJ_CLK_ENABLE();
  __HAL_RCC_GPIOD_CLK_ENABLE();
  __HAL_RCC_GPIOK_CLK_ENABLE();
  __HAL_RCC_GPIOI_CLK_ENABLE();
  __HAL_RCC_GPIOF_CLK_ENABLE();
  __HAL_RCC_GPIOH_CLK_ENABLE();

  /*Configure GPIO pin Output Level */
  HAL_GPIO_WritePin(GPIOB, KBD_LINE0_Pin|KBD_LINE1_Pin|KBD_LINE2_Pin|KBD_LINE3_Pin, GPIO_PIN_SET);

  /*Configure GPIO pin Output Level */
  HAL_GPIO_WritePin(KBD_LED_FR_GPIO_Port, KBD_LED_FR_Pin, GPIO_PIN_RESET);

  /*Configure GPIO pin Output Level */
  HAL_GPIO_WritePin(GPIOI, KBD_LED_RESET_Pin|LCD_DISP_Pin, GPIO_PIN_RESET);

  /*Configure GPIO pin Output Level */
  HAL_GPIO_WritePin(LCD_LED_GPIO_Port, LCD_LED_Pin, GPIO_PIN_RESET);

  /*Configure GPIO pin Output Level */
  HAL_GPIO_WritePin(KBD_LINE4_GPIO_Port, KBD_LINE4_Pin, GPIO_PIN_SET);

  /*Configure GPIO pin Output Level */
  HAL_GPIO_WritePin(USART6_DE_GPIO_Port, USART6_DE_Pin, GPIO_PIN_SET);

  /*Configure GPIO pins : KBD_LINE0_Pin KBD_LINE1_Pin KBD_LINE2_Pin KBD_LINE3_Pin */
  GPIO_InitStruct.Pin = KBD_LINE0_Pin|KBD_LINE1_Pin|KBD_LINE2_Pin|KBD_LINE3_Pin;
  GPIO_InitStruct.Mode = GPIO_MODE_OUTPUT_OD;
  GPIO_InitStruct.Pull = GPIO_NOPULL;
  GPIO_InitStruct.Speed = GPIO_SPEED_FREQ_LOW;
  HAL_GPIO_Init(GPIOB, &GPIO_InitStruct);

  /*Configure GPIO pin : KBD_LED_FR_Pin */
  GPIO_InitStruct.Pin = KBD_LED_FR_Pin;
  GPIO_InitStruct.Mode = GPIO_MODE_OUTPUT_PP;
  GPIO_InitStruct.Pull = GPIO_NOPULL;
  GPIO_InitStruct.Speed = GPIO_SPEED_FREQ_LOW;
  HAL_GPIO_Init(KBD_LED_FR_GPIO_Port, &GPIO_InitStruct);

  /*Configure GPIO pins : KBD_LED_RESET_Pin LCD_DISP_Pin */
  GPIO_InitStruct.Pin = KBD_LED_RESET_Pin|LCD_DISP_Pin;
  GPIO_InitStruct.Mode = GPIO_MODE_OUTPUT_PP;
  GPIO_InitStruct.Pull = GPIO_NOPULL;
  GPIO_InitStruct.Speed = GPIO_SPEED_FREQ_LOW;
  HAL_GPIO_Init(GPIOI, &GPIO_InitStruct);

  /*Configure GPIO pin : LCD_LED_Pin */
  GPIO_InitStruct.Pin = LCD_LED_Pin;
  GPIO_InitStruct.Mode = GPIO_MODE_OUTPUT_PP;
  GPIO_InitStruct.Pull = GPIO_NOPULL;
  GPIO_InitStruct.Speed = GPIO_SPEED_FREQ_LOW;
  HAL_GPIO_Init(LCD_LED_GPIO_Port, &GPIO_InitStruct);

  /*Configure GPIO pin : KBD_LINE4_Pin */
  GPIO_InitStruct.Pin = KBD_LINE4_Pin;
  GPIO_InitStruct.Mode = GPIO_MODE_OUTPUT_OD;
  GPIO_InitStruct.Pull = GPIO_NOPULL;
  GPIO_InitStruct.Speed = GPIO_SPEED_FREQ_LOW;
  HAL_GPIO_Init(KBD_LINE4_GPIO_Port, &GPIO_InitStruct);

  /*Configure GPIO pin : USART6_DE_Pin */
  GPIO_InitStruct.Pin = USART6_DE_Pin;
  GPIO_InitStruct.Mode = GPIO_MODE_OUTPUT_PP;
  GPIO_InitStruct.Pull = GPIO_NOPULL;
  GPIO_InitStruct.Speed = GPIO_SPEED_FREQ_LOW;
  HAL_GPIO_Init(USART6_DE_GPIO_Port, &GPIO_InitStruct);

  /*Configure GPIO pins : KBD_IN1_Pin KBD_IN0_Pin KBD_IN4_Pin KBD_IN3_Pin
                           KBD_IN2_Pin */
  GPIO_InitStruct.Pin = KBD_IN1_Pin|KBD_IN0_Pin|KBD_IN4_Pin|KBD_IN3_Pin
                          |KBD_IN2_Pin;
  GPIO_InitStruct.Mode = GPIO_MODE_INPUT;
  GPIO_InitStruct.Pull = GPIO_NOPULL;
  HAL_GPIO_Init(GPIOF, &GPIO_InitStruct);

}

/* MPU Configuration */

void MPU_Config(void)
{
  MPU_Region_InitTypeDef MPU_InitStruct;

  /* Disables the MPU */
  HAL_MPU_Disable();
    /**Initializes and configures the Region and the memory to be protected
    */
  MPU_InitStruct.Enable = MPU_REGION_ENABLE;
  MPU_InitStruct.Number = MPU_REGION_NUMBER0;
  MPU_InitStruct.BaseAddress = 0xC0000000;
  MPU_InitStruct.Size = MPU_REGION_SIZE_4MB;
  MPU_InitStruct.SubRegionDisable = 0x0;
  MPU_InitStruct.TypeExtField = MPU_TEX_LEVEL0;
  MPU_InitStruct.AccessPermission = MPU_REGION_FULL_ACCESS;
  MPU_InitStruct.DisableExec = MPU_INSTRUCTION_ACCESS_ENABLE;
  MPU_InitStruct.IsShareable = MPU_ACCESS_NOT_SHAREABLE;
  MPU_InitStruct.IsCacheable = MPU_ACCESS_CACHEABLE;
  MPU_InitStruct.IsBufferable = MPU_ACCESS_NOT_BUFFERABLE;

  HAL_MPU_ConfigRegion(&MPU_InitStruct);

  /* Enables the MPU */
  HAL_MPU_Enable(MPU_PRIVILEGED_DEFAULT);

}

void _Error_Handler(char *file, int line)
{
  while(1)
  {
  }
}

/************************ (C) COPYRIGHT STMicroelectronics *****END OF FILE****/
